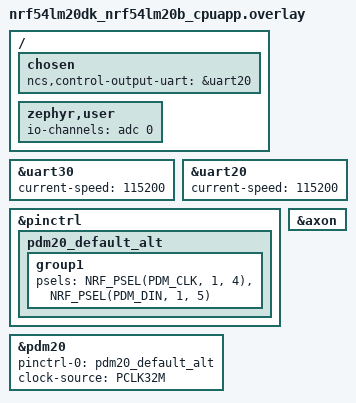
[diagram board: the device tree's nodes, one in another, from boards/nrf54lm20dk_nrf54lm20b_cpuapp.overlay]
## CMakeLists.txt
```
#
# Copyright (c) 2026 Nordic Semiconductor ASA
#
# SPDX-License-Identifier: LicenseRef-Nordic-5-Clause
#

cmake_minimum_required(VERSION 3.20.0)

find_package(Zephyr REQUIRED HINTS $ENV{ZEPHYR_BASE})
project(ww_kws)

target_sources(app PRIVATE
  src/main.c

  src/control_output.c
  src/dmic.c
  src/leds.c

  src/ww/wakeword.c
  src/ww/nrf_edgeai_generated/nrf_edgeai_user_model.c

  src/kws/kws.c
  src/kws/nrf_edgeai_generated/nrf_edgeai_user_model.c
  
  src/keycap/keycap.c
  src/keycap/nrf_edgeai_generated/nrf_edgeai_user_model.c
  src/adc/adc.c
  
)

target_sources_ifdef(CONFIG_MODELS_OBSERVABILITY_MDS app PRIVATE src/ble/ble_mds.c)
```

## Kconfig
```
#
# Copyright (c) 2026 Nordic Semiconductor ASA
#
# SPDX-License-Identifier: LicenseRef-Nordic-5-Clause
#

menu "Wakeword and Keyword Spotting application"

choice APP_MODE
	prompt "Application mode"
	default APP_MODE_KEYSNOOP

config APP_MODE_WW_GATED_KWS
	bool "Wakeword-gated keyword spotting mode"
	help
	  Run keyword spotting model only after wakeword was detected. After configurable duration
	  without any keyword spotted switch back to wakeword detection.

config APP_MODE_WW_ONLY
	bool "Wakeword detection only mode"
	help
	  Run wakeword detection continuously without switching to keyword spotting.

config APP_MODE_KWS_ONLY
	bool "Keyword spotting only mode"
	help
	  Run keyword spotting continuously without the need to detect wakeword first.

config APP_MODE_KEYSNOOP
	bool "Keyboard snooper"
	help
	  Run keyboard sniffer


endchoice

config WW_PROBABILITY_THRESHOLD
	int "Wakeword probability threshold"
	range 0 1000
	default 990
	help
	   Probability threshold for wakeword detection model. The value is expressed in units of
	   1/1000.

config WW_HISTORY_SIZE
	int "Size of wakeword predictions history"
	range 1 32
	default 20
	help
	  Size of history of previous results from wakeword detection model. Each entry corresponds
	  to 30 milliseconds of past audio.

config WW_COUNT_THRESHOLD
	int "Threshold for wakeword detection from predictions history"
	range 1 WW_HISTORY_SIZE
	default 15
	help
	  Number of predictions above threshold in predictions history required to confirm wakeword
	  detection.

config KWS_PERIOD_MS
	int "Length of keyword spotting window in wakeword-gated mode"
	default 3000

config KWS_EMA_ALPHA
	int "Exponential moving average coefficient for class probability"
	range 0 1000
	default 120
	help
	  Coefficient for new entries in exponential moving average calculation for average class
	  probability. The value is expressed in units of 1/1000.

config MODELS_OBSERVABILITY
	bool "Edge AI observability metrics"
	depends on NRF_EDGEAI_OBSV
	depends on NRF_EDGEAI_OBSV_MEMFAULT
	depends on NRF_EDGEAI_OBSV_METRIC_PROBS_DISTRIBUTION
	depends on NRF_EDGEAI_OBSV_METRIC_TRANSITION_MATRIX || APP_MODE_WW_ONLY
	depends on NRF_EDGEAI_OBSV_MEMFAULT_MAX_CONTEXTS >= 2 || !APP_MODE_WW_GATED_KWS
	help
	  Wire observability into the bundled models. Each model file owns its observability context
	  and Memfault transport binding.

if MODELS_OBSERVABILITY

config MODELS_OBSERVABILITY_MDS
	def_bool y
	depends on BT_MDS
	depends on BT_SMP
	depends on NRF_EDGEAI_OBSV_MEMFAULT_AUTO_COLLECT

endif # MODELS_OBSERVABILITY

endmenu

source "Kconfig.zephyr"
```

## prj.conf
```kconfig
#
# Copyright (c) 2026 Nordic Semiconductor
#
# SPDX-License-Identifier: LicenseRef-Nordic-5-Clause
#

# nRF Edge AI
CONFIG_NRF_EDGEAI=y

# nRF Edge AI dependencies
CONFIG_NRF_AXON=y
CONFIG_FPU=y

# Size of interlayer buffer to fit model
CONFIG_NRF_AXON_INTERLAYER_BUFFER_SIZE=6656

# Size of psum buffer to fit model
CONFIG_NRF_AXON_PSUM_BUFFER_SIZE=0

# Enable sensor, button and LED libraries
CONFIG_GPIO=y
CONFIG_AUDIO=y
CONFIG_AUDIO_DMIC=y

# Enable logging and assert
CONFIG_LOG=y
CONFIG_CONSOLE=y
CONFIG_UART_CONSOLE=y
CONFIG_SERIAL=y
CONFIG_ASSERT=y
CONFIG_LOG_DEFAULT_LEVEL=3

CONFIG_UART_ASYNC_API=y



# Enable nrfx drivers #
CONFIG_NRFX_SAADC=y
CONFIG_NRFX_GPPI=y
CONFIG_NRFX_TIMER=y
```

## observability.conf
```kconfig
#
# Copyright (c) 2026 Nordic Semiconductor
#
# SPDX-License-Identifier: LicenseRef-Nordic-5-Clause
#

# Models observability and its dependencies
CONFIG_MODELS_OBSERVABILITY=y
CONFIG_ZCBOR=y
CONFIG_NRF_EDGEAI_OBSV=y
CONFIG_NRF_EDGEAI_OBSV_MAX_CLASSES=18
CONFIG_NRF_EDGEAI_OBSV_ENCODE=y
CONFIG_NRF_EDGEAI_OBSV_METRIC_PROBS_DISTRIBUTION=y
CONFIG_NRF_EDGEAI_OBSV_METRIC_TRANSITION_MATRIX=y
CONFIG_NRF_EDGEAI_OBSV_MEMFAULT=y
CONFIG_NRF_EDGEAI_OBSV_MEMFAULT_MAX_CONTEXTS=2

# Auto collect metrics
CONFIG_NRF_EDGEAI_OBSV_MEMFAULT_AUTO_COLLECT=y
CONFIG_SYSTEM_WORKQUEUE_STACK_SIZE=4096

# Bluetooth MDS
CONFIG_BT=y
CONFIG_BT_SMP=y
CONFIG_BT_PERIPHERAL=y
CONFIG_BT_DEVICE_NAME="Keysnoop"
CONFIG_BT_PRIVACY=y
CONFIG_BT_MDS=y

CONFIG_BT_BUF_ACL_RX_SIZE=251
CONFIG_BT_L2CAP_TX_MTU=247
CONFIG_BT_BUF_ACL_TX_SIZE=251
CONFIG_BT_CTLR_DATA_LENGTH_MAX=251

# Enable bonding
CONFIG_SETTINGS=y
CONFIG_ZMS=y
CONFIG_BT_SETTINGS=y
CONFIG_FLASH=y
CONFIG_FLASH_PAGE_LAYOUT=y
CONFIG_FLASH_MAP=y

# Memfault settings
CONFIG_MEMFAULT=y
CONFIG_MEMFAULT_USER_CONFIG_ENABLE=n
CONFIG_MEMFAULT_NCS_PROJECT_KEY=""
CONFIG_MEMFAULT_NCS_DEVICE_ID_STATIC=y
CONFIG_MEMFAULT_NCS_DEVICE_ID="keysnoop-obsv"
```

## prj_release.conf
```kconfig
#
# Copyright (c) 2026 Nordic Semiconductor
#
# SPDX-License-Identifier: LicenseRef-Nordic-5-Clause
#

# ---------------------------------------------------------------------------
# Core application dependencies
# ---------------------------------------------------------------------------

# nRF Edge AI inference runtime and Axon NPU driver
CONFIG_NRF_EDGEAI=y

# nRF Edge AI dependencies
CONFIG_NRF_AXON=y
CONFIG_FPU=y

# Size of interlayer buffer to fit model
CONFIG_NRF_AXON_INTERLAYER_BUFFER_SIZE=6656

# Size of psum buffer to fit model
CONFIG_NRF_AXON_PSUM_BUFFER_SIZE=0

# ---------------------------------------------------------------------------
# Required peripherals
# ---------------------------------------------------------------------------


# Enable nrfx drivers #
CONFIG_NRFX_SAADC=y
CONFIG_NRFX_GPPI=y
CONFIG_NRFX_TIMER=y



# Enable GPIO for LEDs and AUDIO for DMIC
CONFIG_GPIO=y
CONFIG_AUDIO=y
CONFIG_AUDIO_DMIC=y
CONFIG_SERIAL=y
CONFIG_UART_ASYNC_API=y

# ---------------------------------------------------------------------------
# Power management
# ---------------------------------------------------------------------------
CONFIG_PM_DEVICE=y
CONFIG_PM_DEVICE_RUNTIME=y


# ---------------------------------------------------------------------------
# Disable all debug and logging infrastructure
# ---------------------------------------------------------------------------
CONFIG_LOG=n
CONFIG_PRINTK=n
CONFIG_CONSOLE=n
CONFIG_UART_CONSOLE=n
CONFIG_SHELL=n
CONFIG_BOOT_BANNER=n
CONFIG_NCS_BOOT_BANNER=n
CONFIG_ASSERT=n
CONFIG_DEBUG=n

# ---------------------------------------------------------------------------
# Library size reduction
# ---------------------------------------------------------------------------
CONFIG_CBPRINTF_NANO=y

# ---------------------------------------------------------------------------
# Compiler and linker optimizations
# ---------------------------------------------------------------------------
CONFIG_SPEED_OPTIMIZATIONS=y
CONFIG_ISR_TABLES_LOCAL_DECLARATION=y
```

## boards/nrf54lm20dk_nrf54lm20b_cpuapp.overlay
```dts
/*
 * Copyright (c) 2026 Nordic Semiconductor ASA
 *
 * SPDX-License-Identifier: LicenseRef-Nordic-5-Clause
 */

/ {
	chosen {
		ncs,control-output-uart = &uart20;
		/* ncs,control-output-uart = &uart30;*/
	};
};

/ {
    zephyr,user {
        io-channels = <&adc 0>;  
    };
};

&uart30 {
	status = "okay";
	current-speed = <115200>;
};

/* Set high baud rate on the console UART */
&uart20 { /* zephyr,console UART */
    current-speed = <115200>;   /* 1Mbaud */
    status = "okay";
};

&pinctrl {
	pdm20_default_alt: pdm20_default_alt {
		group1 {
			psels = <NRF_PSEL(PDM_CLK, 1, 4)>,
				<NRF_PSEL(PDM_DIN, 1, 5)>;
		};
	};
};

dmic_dev: &pdm20 {
	status = "okay";
	pinctrl-0 = <&pdm20_default_alt>;
	pinctrl-names = "default";
	clock-source = "PCLK32M";
};

&axon {
	status = "okay";
};
```

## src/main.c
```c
/*
 * Copyright (c) 2026 Nordic Semiconductor ASA
 *
 * SPDX-License-Identifier: LicenseRef-Nordic-5-Clause
 */

#include <stddef.h>
#include <stdint.h>

#include <zephyr/audio/dmic.h>
#include <zephyr/device.h>
#include <zephyr/devicetree.h>
#include <zephyr/logging/log.h>

#include "ble/ble_mds.h"
#include "control_output.h"
#include "dmic.h"
#include "kws/kws.h"
#include "leds.h"
#include "ww/wakeword.h"
#include "keycap/keycap.h"
#include "adc/adc.h"

LOG_MODULE_REGISTER(main);

#define DMIC_READ_TIMEOUT 100

#if IS_ENABLED(APP_MODE_KEYSNOOP) 
static const struct device *const dmic_dev = NULL;
#else
static const struct device *const dmic_dev = DEVICE_DT_GET(DT_NODELABEL(dmic_dev));
#endif

static int ww_loop(void)
{
	int err;
	void *audio_buffer;
	size_t audio_buffer_size;
	bool ww_detected;

	ww_reset();

	print_control_output((struct control_message){CONTROL_MESSAGE_WAITING_WW});

	while (true) {
		err = dmic_read(dmic_dev, 0, &audio_buffer, &audio_buffer_size, DMIC_READ_TIMEOUT);
		if (err < 0) {
			LOG_ERR("Failed to read from DMIC (err %d)", err);
			return err;
		}

		err = ww_process(audio_buffer, DMIC_SAMPLES_IN_BLOCK, &ww_detected);
		if (err == -EBUSY) {
			/* More data is needed. */
			continue;
		} else if (err < 0) {
			LOG_ERR("Wakeword detection failed (err %d)", err);
			return err;
		}

		if (ww_detected) {
			print_control_output((struct control_message){CONTROL_MESSAGE_WW_DETECTED});
			if (IS_ENABLED(CONFIG_APP_MODE_WW_ONLY)) {
				leds_blink_led0();
			} else {
				return 0;
			}
		}
	}
}

static int kws_loop(void)
{
	int err;
	void *audio_buffer;
	size_t audio_buffer_size;
	struct kws_prediction prediction;

	uint32_t spotting_timeout = k_uptime_get_32() + CONFIG_KWS_PERIOD_MS;

	kws_reset();

	print_control_output((struct control_message){.type = CONTROL_MESSAGE_WAITING_KW});

	while (IS_ENABLED(CONFIG_APP_MODE_KWS_ONLY) || spotting_timeout > k_uptime_get_32()) {
		err = dmic_read(dmic_dev, 0, &audio_buffer, &audio_buffer_size, DMIC_READ_TIMEOUT);
		if (err < 0) {
			LOG_ERR("Failed to read from DMIC (err %d)", err);
			return err;
		}

		err = kws_process(audio_buffer, DMIC_SAMPLES_IN_BLOCK, &prediction);
		if (err == -EBUSY) {
			/* More data is needed. */
			continue;
		} else if (err) {
			LOG_ERR("Keyword spotting failed (err %d)", err);
			return err;
		}

		if (prediction.valid) {
			leds_blink_led1();
			spotting_timeout = k_uptime_get_32() + CONFIG_KWS_PERIOD_MS;
			print_control_output(
				(struct control_message){.type = CONTROL_MESSAGE_KW_SPOTTED,
							 .kw_class = prediction.class,
							 .name = prediction.name});
		}
	}

	print_control_output((struct control_message){.type = CONTROL_MESSAGE_TIMEOUT_KWS});

	return 0;
}




static int keycap_loop(void)
{
	int err;
	uint16_t *audio_buffer;
	size_t audio_buffer_size;
	keycap_prediction_t prediction;

	uint32_t spotting_timeout = k_uptime_get_32() + CONFIG_KWS_PERIOD_MS;


	keycap_reset();

	print_control_output((struct control_message){.type = CONTROL_MESSAGE_WAITING_KW});
	for (;;) {
		if (k_sem_take(&burst_data_ready, K_NO_WAIT) != 0) {
			k_sleep(K_MSEC(5));
			continue;
		}
		audio_buffer = (uint16_t*)adc_burst_data;
		err = keycap_process(audio_buffer, SAADC_BUFFER_NUMSAMPLES, &prediction);
		if (err == -EBUSY) {
			/* More data is needed. */
			LOG_INF("bizzy");
			continue;
		} else if (err) {
			LOG_ERR("Keycapture failed (err %d)", err);
			return err;
		}

		if (prediction.valid) {
			leds_blink_led1();
			// LOG_WRN("Pred %s", prediction.name);
			print_control_output(
				(struct control_message){.type = CONTROL_MESSAGE_KEY_SNOOPED_LOG,
							 .kw_class = prediction.class,
							 .name = prediction.name,
							 .confidence = prediction.confidence,
							 .inference_time_us = prediction.inference_us});
		} else {
			// LOG_INF("No pred");
		}
	}

	print_control_output((struct control_message){.type = CONTROL_MESSAGE_TIMEOUT_KWS});

	return 0;
}

int main_loop(void)
{
	int err;

	if (IS_ENABLED(CONFIG_APP_MODE_KEYSNOOP)) {
		LOG_ERR("Keyboard snoop mode!");
	} else {
		
		LOG_ERR("mic init!");
		err = dmic_init();
		if (err) {
			LOG_ERR("Err with dmic");
			return err;
		}
	}

	LOG_INF("LEDS init");
	err = leds_init();
	if (err) {
			LOG_ERR("Err with leds");
		return err;
	}

	LOG_INF("ctrlout init");
	err = control_output_init();
	if (err) {
			LOG_ERR("Err with ctrlout");
		return err;
	} else {
		LOG_INF("ALL GOOD");
	}

	if (IS_ENABLED(CONFIG_APP_MODE_KEYSNOOP)) {
		LOG_INF("keycap  init");
		err = keycap_init();
		if (err) {
			LOG_ERR("Err with keycap");
			return err;
		}
	} else {
		LOG_INF("NO KEYSNOOP?");
	}


	if (IS_ENABLED(CONFIG_APP_MODE_WW_GATED_KWS) || IS_ENABLED(CONFIG_APP_MODE_WW_ONLY)) {
		LOG_INF("ww  init");
		err = ww_init();
		if (err) {
			return err;
		}
	}

	if (IS_ENABLED(CONFIG_APP_MODE_WW_GATED_KWS) || IS_ENABLED(CONFIG_APP_MODE_KWS_ONLY)) {
		LOG_INF("kws  init");
		err = kws_init();
		if (err) {
			return err;
		}
	}

	LOG_INF("ble  init");
	err = init_app_ble();
	if (err) {
		return err;
	}

	LOG_INF("Initialization completed, check output on VCOM0");

	if (IS_ENABLED(CONFIG_APP_MODE_KEYSNOOP) ) {
		adc_init();
	} else {
		LOG_INF("dmic trig");
		err = dmic_trigger(dmic_dev, DMIC_TRIGGER_START);
		if (err < 0) {
			LOG_ERR("Failed to start DMIC (err %d)", err);
			return err;
		}
	}

	while (true) {
		if (IS_ENABLED(CONFIG_APP_MODE_WW_GATED_KWS) ||
		    IS_ENABLED(CONFIG_APP_MODE_WW_ONLY)) {
			err = ww_loop();
			if (err) {
				return err;
			}
		}

		if (IS_ENABLED(CONFIG_APP_MODE_WW_GATED_KWS)) {
			leds_on_led0();
		}

		if (IS_ENABLED(CONFIG_APP_MODE_WW_GATED_KWS) ||
		    IS_ENABLED(CONFIG_APP_MODE_KWS_ONLY)) {
			err = kws_loop();
			if (err) {
				return err;
			}
		}

		if (IS_ENABLED(CONFIG_APP_MODE_KEYSNOOP) ) {
			LOG_INF("snoop loop ");
			err = keycap_loop();
			if (err) {
				return err;
			}

		}

		if (IS_ENABLED(CONFIG_APP_MODE_WW_GATED_KWS)) {
			leds_off_led0();
		}
	}

	return 0;
}
int main(void) {
	for(;;) {
	main_loop();
	}
}
```

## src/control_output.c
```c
/*
 * Copyright (c) 2026 Nordic Semiconductor ASA
 *
 * SPDX-License-Identifier: LicenseRef-Nordic-5-Clause
 */

#include <stdalign.h>
#include <stddef.h>
#include <stdio.h>

#include <zephyr/device.h>
#include <zephyr/devicetree.h>
#include <zephyr/drivers/uart.h>
#include <zephyr/kernel.h>
#include <zephyr/logging/log.h>
#include <zephyr/sys/atomic.h>

#include "control_output.h"

LOG_MODULE_REGISTER(control_output);

struct k_work control_output_work;

K_MSGQ_DEFINE(control_msg_queue, sizeof(struct control_message), 10,
	      alignof(struct control_message));

static const char *const messages[] = {
	[CONTROL_MESSAGE_WAITING_WW] = "Waiting for wakeword\r\n",
	[CONTROL_MESSAGE_WW_DETECTED] = "Wakeword detected\r\n",

	[CONTROL_MESSAGE_WAITING_KW] = "Waiting for keywords\r\n",
	[CONTROL_MESSAGE_KW_SPOTTED] = "Key snooped:\t%s\r\n",
	[CONTROL_MESSAGE_KEY_SNOOPED] = "%s",
	[CONTROL_MESSAGE_KEY_SNOOPED_LOG] = "Key snooped:\t%s\t%f [inf time: %i us]\r\n",
	[CONTROL_MESSAGE_TIMEOUT_KWS] = "Keyword spotting window timeout\r\n",
};

BUILD_ASSERT(CONTROL_MESSAGE_COUNT == ARRAY_SIZE(messages),
	     "Mismatch between control_message_type and messages size");

static const struct device *uart_dev = DEVICE_DT_GET(DT_CHOSEN(ncs_control_output_uart));
static atomic_t uart_busy;

static void uart_cb(const struct device *dev, struct uart_event *evt, void *user_data)
{
	int err;

	if (evt->type == UART_TX_DONE) {
		atomic_set(&uart_busy, false);

		if (k_msgq_num_used_get(&control_msg_queue) == 0) {
			return;
		}

		err = k_work_submit(&control_output_work);
		if (err < 0) {
			LOG_ERR("Failed to submit work (err %d)", err);
		}
	}
}

static void control_output_work_handler(struct k_work *work)
{
	int err;
	struct control_message message_item;

	static char output_buffer[60];
	const char *buffer = NULL;
	size_t buffer_len = 0;

	if (atomic_get(&uart_busy)) {
		return;
	}

	/* Peek message to not lose it if uart_tx fails. */
	err = k_msgq_peek(&control_msg_queue, &message_item);
	if (err) {
		return;
	}

	atomic_set(&uart_busy, true);

	switch (message_item.type) {
	case CONTROL_MESSAGE_WAITING_WW:
	case CONTROL_MESSAGE_WW_DETECTED:
	case CONTROL_MESSAGE_WAITING_KW:
	case CONTROL_MESSAGE_TIMEOUT_KWS:
		buffer = messages[message_item.type];
		buffer_len = strlen(buffer);
		break;

	case CONTROL_MESSAGE_KW_SPOTTED: {
		int ret = snprintf(output_buffer, sizeof(output_buffer),
				   messages[message_item.type], message_item.name);

		if (ret < 0) {
			atomic_set(&uart_busy, false);
			k_msgq_get(&control_msg_queue, &message_item, K_NO_WAIT);
			LOG_ERR("snprintf failed (%d)", ret);
			return;
		}
		buffer = output_buffer;
		buffer_len = MIN((size_t)ret, sizeof(output_buffer) - 1);
		break;
	}
		
	case CONTROL_MESSAGE_KEY_SNOOPED_LOG: {
		int ret = snprintf(output_buffer, sizeof(output_buffer),
				   messages[message_item.type], message_item.name, message_item.confidence, message_item.inference_time_us);

		if (ret < 0) {
			atomic_set(&uart_busy, false);
			k_msgq_get(&control_msg_queue, &message_item, K_NO_WAIT);
			LOG_ERR("snprintf failed (%d)", ret);
			return;
		}
		buffer = output_buffer;
		buffer_len = MIN((size_t)ret, sizeof(output_buffer) - 1);
		break;
	}
		
	case CONTROL_MESSAGE_KEY_SNOOPED: {
		int ret = snprintf(output_buffer, sizeof(output_buffer),
				   messages[message_item.type], message_item.name);

		if (ret < 0) {
			atomic_set(&uart_busy, false);
			k_msgq_get(&control_msg_queue, &message_item, K_NO_WAIT);
			LOG_ERR("snprintf failed (%d)", ret);
			return;
		}
		buffer = output_buffer;
		buffer_len = MIN((size_t)ret, sizeof(output_buffer) - 1);
		break;
	}
	default:
		atomic_set(&uart_busy, false);
		k_msgq_get(&control_msg_queue, &message_item, K_NO_WAIT);
		LOG_WRN("Unhandled case");
		return;
	}

	err = uart_tx(uart_dev, buffer, buffer_len, 0);
	if (err) {
		atomic_set(&uart_busy, false);
		LOG_ERR("Failed to transmit data (err %d)", err);
		return;
	}

	k_msgq_get(&control_msg_queue, &message_item, K_NO_WAIT);
}

int control_output_init(void)
{
	int err;

	if (!device_is_ready(uart_dev)) {
		LOG_ERR("Device is not ready");
		return -ENODEV;
	}
	LOG_ERR("Setting callback");
	err = uart_callback_set(uart_dev, uart_cb, NULL);
	if (err) {
		LOG_ERR("Failed to set UART callback (err %d)", err);
	}

	LOG_ERR("kworkinit");
	k_work_init(&control_output_work, control_output_work_handler);
	LOG_ERR("kworkinit done");

	return err;
}

void print_control_output(const struct control_message message)
{
	int err;

	err = k_msgq_put(&control_msg_queue, &message, K_NO_WAIT);
	if (err) {
		LOG_ERR("Failed to put message in queue (err %d)", err);
		return;
	}

	err = k_work_submit(&control_output_work);
	if (err < 0) {
		LOG_ERR("Failed to submit work (err %d)", err);
	}
}
```

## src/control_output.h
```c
/*
 * Copyright (c) 2026 Nordic Semiconductor ASA
 *
 * SPDX-License-Identifier: LicenseRef-Nordic-5-Clause
 */

/**
 * @defgroup control_output Printing control output functions
 * @{
 * @ingroup ww_kws
 */

#ifndef __CONTROL_OUTPUT_H__
#define __CONTROL_OUTPUT_H__

#include <stdint.h>

#ifdef __cplusplus
extern "C" {
#endif /* __cplusplus */

/**
 * @brief Control message type.
 */
enum control_message_type {
	CONTROL_MESSAGE_WAITING_WW,
	CONTROL_MESSAGE_WW_DETECTED,

	CONTROL_MESSAGE_WAITING_KW,
	CONTROL_MESSAGE_KW_SPOTTED,
	CONTROL_MESSAGE_TIMEOUT_KWS,
	CONTROL_MESSAGE_KEY_SNOOPED,
	CONTROL_MESSAGE_KEY_SNOOPED_LOG,

	CONTROL_MESSAGE_COUNT
};

/**
 * @brief Control message.
 */
struct control_message {
	enum control_message_type type;
	uint16_t kw_class;
	const char *name;
	float confidence;
	uint16_t inference_time_us;
};

/**
 * @brief Initialize control output backend.
 *
 * @return Operation status, 0 for success.
 */
int control_output_init(void);

/**
 * @brief Print the control messages to @c ncs_control_output_uart serial.
 *
 * @param message Control message to be printed.
 */
void print_control_output(const struct control_message message);

#ifdef __cplusplus
}
#endif /* __cplusplus */

#endif /* __CONTROL_OUTPUT_H__ */

/**
 * @}
 */
```
